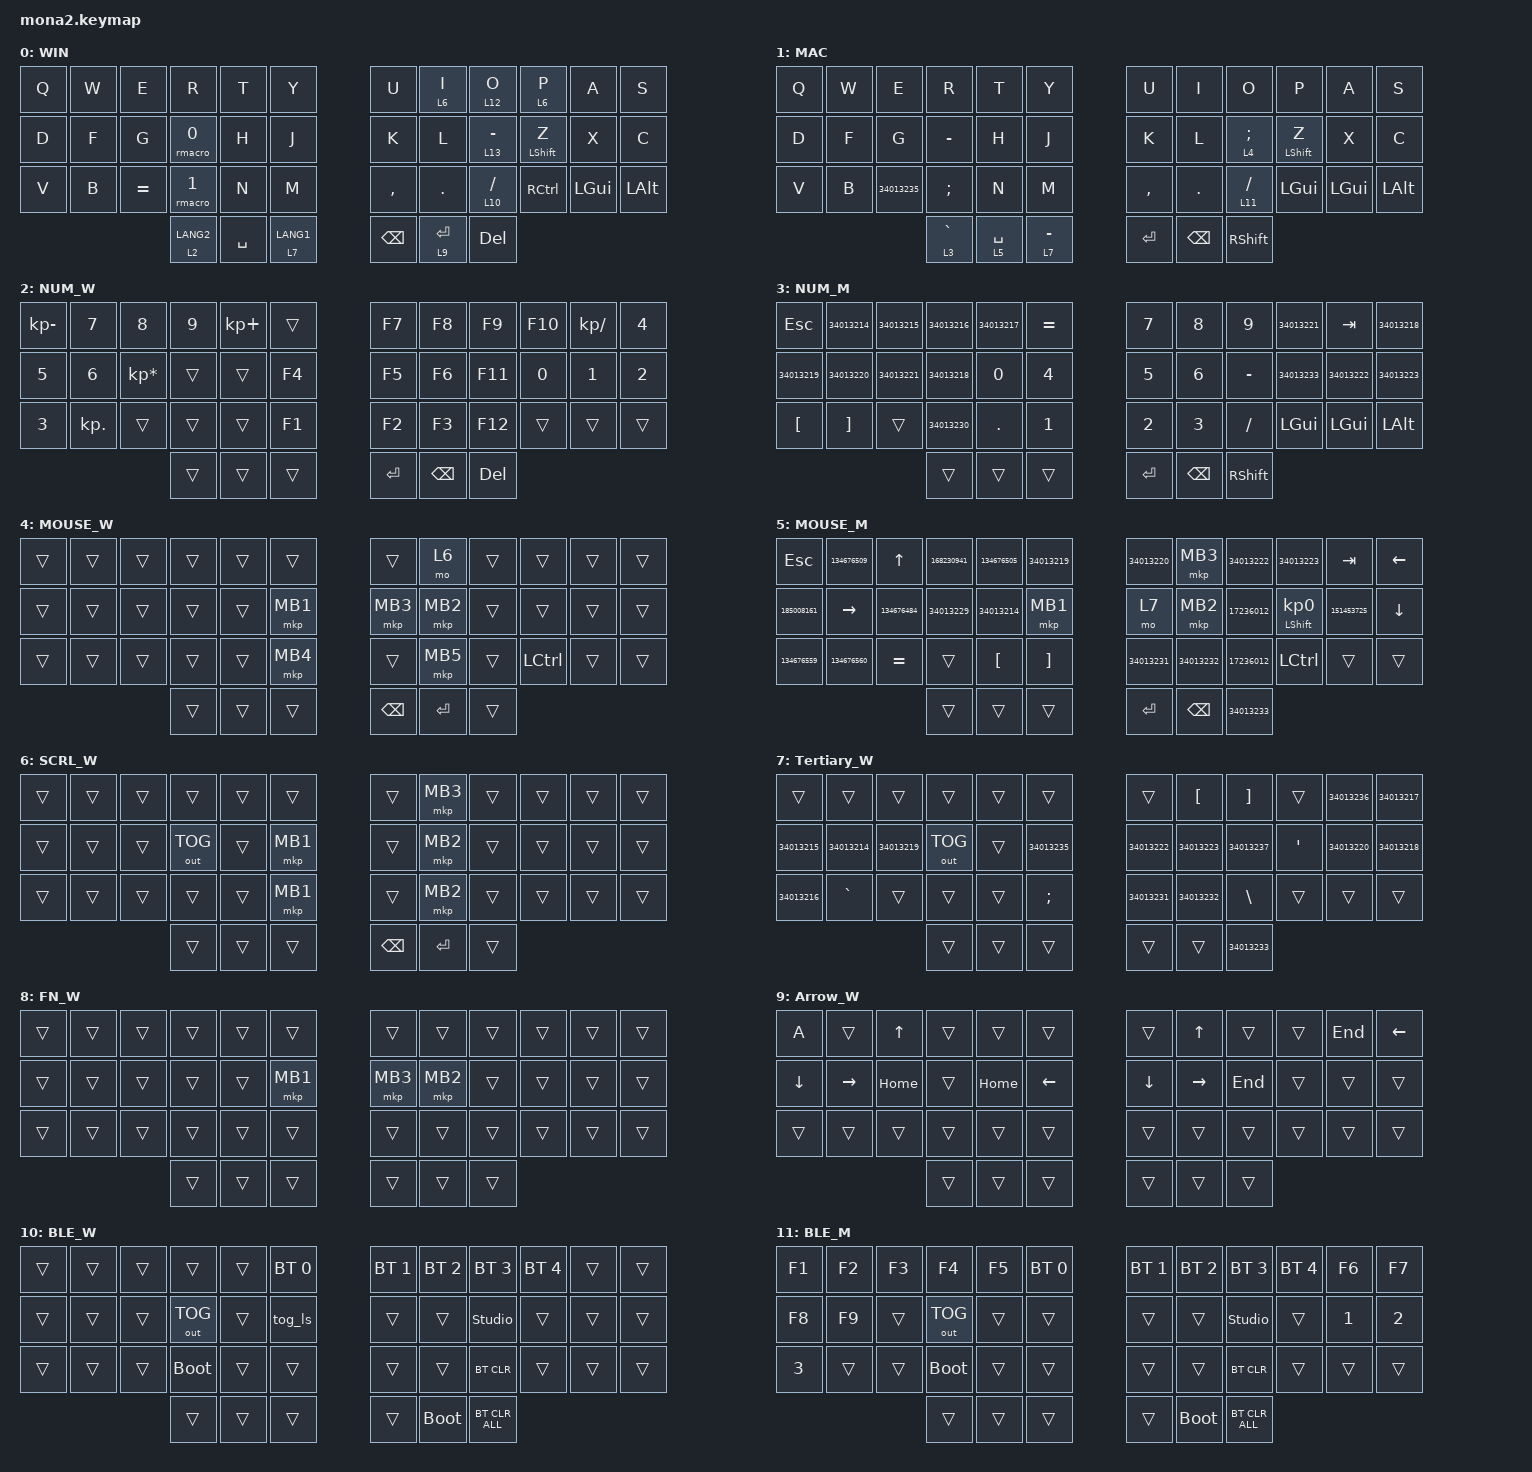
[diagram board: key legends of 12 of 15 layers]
#include <input/processors.dtsi>
#include <dt-bindings/zmk/input_transform.h>
#include <zephyr/dt-bindings/input/input-event-codes.h>
#include <behaviors/runtime-sensor-rotate.dtsi>
#include <behaviors.dtsi>
/* JIS配列のPCでもUS配列の刻印どおりに記号を入力するためのモジュール
   (modules/jis_layout_shift)。`&kp` を配列対応版に差し替え、`&tog_ls` で
   JIS変換の ON/OFF を切り替える。`&kp` のデバイス名 (key_press) と表示名は
   変えていないので、DYA Studio で保存済みのキーマップ / マクロ / コンボはそのまま使える。
   必ず behaviors.dtsi の後に include すること。 */
#include <jis_layout_shift.dtsi>
/* DYA Studio から作成したマクロを呼び出す `&rmacro <slot>` を定義する。
   slot は 0 〜 CONFIG_ZMK_RUNTIME_MACRO_COUNT-1 (現状 0〜7)。
   どのマクロがどのスロットに入っているかは DYA Studio のマクロ一覧で確認する。
   キーへの割り当ては DYA Studio のキーマップエディタからも行える。 */
#include <behaviors/runtime_macro.dtsi>
/* デフォルトレイヤー変更 behavior `&df`。
   DYA Studio の「OSごとのデフォルトレイヤー」から設定できるほか、
   キーマップエディタで `&df DF_SEL <layer>` / `&df DF_INC` を
   任意のキーに割り当てられる。 */
#include <behaviors/default_layer.dtsi>
#include <dt-bindings/zmk_behavior_default_layer/default_layer.h>
#include <dt-bindings/zmk/bt.h>
#include <dt-bindings/zmk/keys.h>
#include <dt-bindings/zmk/outputs.h>
#include <dt-bindings/zmk/pointing.h>

/* ZMK 側で 10 が定義済みなので警告回避のため一旦 undef */

#undef ZMK_POINTING_DEFAULT_SCRL_VAL

#define ZMK_POINTING_DEFAULT_SCRL_VAL 100


/ {
    behaviors {
        mg_set_0: behavior_mg_set_0 {
            compatible = "zmk,behavior-mg-set-fixed";
            #binding-cells = <0>;
            display-name = "Mouse Gesture Key 0";
        };

        mg_set_1: behavior_mg_set_1 {
            compatible = "zmk,behavior-mg-set-fixed";
            #binding-cells = <0>;
            display-name = "Mouse Gesture Key 1";
        };

        mg_set_2: behavior_mg_set_2 {
            compatible = "zmk,behavior-mg-set-fixed";
            #binding-cells = <0>;
            display-name = "Mouse Gesture Key 2";
        };
    };
};

&mt {
    flavor = "balanced";
    quick-tap-ms = <0>;
};

&lt {
    quick-tap-ms = <200>;
    flavor = "balanced";
};

&msc {
    delay-ms = <0>;
    time-to-max-speed-ms = <0>;
    acceleration-exponent = <0>;
};

/ {
    /* ─────────────────────────────────────────────────────────────
       コンボ (DYA Studio から編集可能)

       旧 `combos { compatible = "zmk,combos"; }` はコンパイル時固定で
       DYA Studio から編集できないため、zmk-feature-runtime-combo の
       「コンパイル時デフォルト」ノードへ移行した。
       ここに書いた内容はフラッシュ直後から有効で、設定を消しても復活する。
       DYA Studio 側で編集するとそのスロットだけ上書きされ、
       Web UI の "Reset to Default" でここの値へ戻せる。

       スロット総数は CONFIG_ZMK_RUNTIME_COMBO_MAX_COMBOS (現状 16)。
       未使用スロット (2〜15) は DYA Studio から自由に追加できる。
       ────────────────────────────────────────────────────────── */
    runtime_combo_defaults {
        compatible = "cormoran,runtime-combo-defaults";

        layer4_ESC {
            slot = <0>;
            display-name = "Layer4 ESC";
            key-positions = <38 39>;
            bindings = <&lt 4 ESC>;
        };

        tab {
            slot = <1>;
            display-name = "Tab";
            key-positions = <11 12>;
            bindings = <&kp TAB>;
        };

        /* I+O (位置7+8) → ボールジェスチャー ウィンドウ切替 */
        gesture_switch_combo {
            slot = <2>;
            display-name = "GestureSwitch";
            key-positions = <7 8>;
            bindings = <&gesture_switch>;
        };
    };

    /* 静的マクロ。キーマップ上で &BT0 / &screenshot などの名前で直接
       参照しているため、そのまま残している (DYA Studio 上では編集不可)。
       DYA Studio から編集したいマクロは Web UI で新規作成し、
       キーに `&rmacro <slot>` を割り当てて使う。 */
    macros {
        /* I+O コンボで発動: 押している間 gesture_switch 層(14)+抑制、
         * 離したら alt_tab_end で Alt+Tab 選択を確定する。 */
        gesture_switch: gesture_switch {
            compatible = "zmk,behavior-macro";
            #binding-cells = <0>;
            bindings = <&macro_press &mo 14>
                     , <&macro_pause_for_release>
                     , <&macro_release &mo 14>
                     , <&macro_tap &alt_tab_end>;
        };

        to_layer_0: to_layer_0 {
            compatible = "zmk,behavior-macro-one-param";
            #binding-cells = <1>;
            bindings = <&to 0 &macro_param_1to1 &kp MACRO_PLACEHOLDER>;
            label = "TO_LAYER_0";
        };

        BT0: BT0 {
            compatible = "zmk,behavior-macro";
            #binding-cells = <0>;
            bindings =
                <&tog_off 0 &tog_off 1>,
                <&macro_wait_time 200>,
                <&bt BT_SEL 0>,
                <&macro_wait_time 500>,
                <&tog_on 0>;

            label = "BT0";
        };

        BT1: BT1 {
            compatible = "zmk,behavior-macro";
            #binding-cells = <0>;
            bindings =
                <&tog_off 0 &tog_off 1>,
                <&macro_wait_time 200>,
                <&bt BT_SEL 1>,
                <&macro_wait_time 500>,
                <&tog_on 1>;

            label = "BT1";
        };

        screenshot: screenshot {
            compatible = "zmk,behavior-macro";
            #binding-cells = <0>;
            bindings =
                <&macro_press>,
                <&kp LEFT_GUI &kp RSHIFT>,
                <&macro_wait_time 20>,
                <&macro_tap>,
                <&kp S>,
                <&macro_release>,
                <&kp LEFT_GUI &kp RSHIFT>;

            label = "SCREENSHOT";
        };

        henkan: henkan {
            compatible = "zmk,behavior-macro";
            #binding-cells = <0>;
            bindings =
                <&macro_press>,
                <&kp LEFT_ALT>,
                <&macro_wait_time 20>,
                <&macro_tap>,
                /* IME 切替キーなので JIS 変換の対象外 (&kp_raw) にする */
                <&kp_raw GRAVE>,
                <&macro_release>,
                <&kp LEFT_ALT>;

            label = "HENKAN";
        };
    };

    behaviors {
        lt_to_layer_0: lt_to_layer_0 {
            compatible = "zmk,behavior-hold-tap";
            label = "LAYER_TAP_TO_0";
            bindings = <&mo>, <&to_layer_0>;

            #binding-cells = <2>;
            tapping-term-ms = <200>;
        };

        tp_repeat_mo1: tp_repeat_mo1 {
            compatible = "zmk,behavior-hold-tap";
            label = "TP_REPEAT_MO1";
            bindings = <&mo>, <&key_repeat>;

            #binding-cells = <2>;
            tapping-term-ms = <200>;
        };

        /* ── torabo-tsuki 流 ボールジェスチャー (Path B 移植) ──────────
         * O 長押し(&lt 12 O) → gesture_tab 層 / − 長押し(&lt 13 MINUS) → gesture_edit 層
         * I+O コンボ → gesture_switch 層(14)
         * ジェスチャー本体 (4方向→動作, always-active) と、その層にいる間の
         * カーソル抑制 (&xy_block) は boards/shields/mona2/mona2_r.overlay 側。
         * 発動キーは素の &lt / &mo なので抑制は listener override が担当する。 */

        /* Alt+Tab ウィンドウ切替 (modules/jis_layout_shift/src/behavior_alt_tab.c)。
         * 初回は LALT を押し続けて param1 をタップ、以降は param2 をタップ。
         * alt_tab_end で LALT を離して確定。central 限定ビルド。 */
        alt_tab: alt_tab {
            compatible = "zmk,behavior-alt-tab";
            #binding-cells = <2>;
        };
        alt_tab_end: alt_tab_end {
            compatible = "zmk,behavior-alt-tab-end";
            #binding-cells = <0>;
        };

        // エンコーダ用 runtime-configurable sensor rotate
        // デフォルトはスクロール (cw=SCRL_DOWN, ccw=SCRL_UP)
        // DYA Studio Web UI から レイヤーごとに cw/ccw の binding を
        // kp C_VOL_UP/DN や kp LEFT/RIGHT などへ動的変更可能

        rsr_default: rsr_default {
            compatible = "zmk,behavior-runtime-sensor-rotate";
            #sensor-binding-cells = <0>;
            tap-ms = <16>;
            cw-binding = <&msc SCRL_DOWN>;
            ccw-binding = <&msc SCRL_UP>;
        };

        tog_on: toggle_layer_on_only {
            compatible = "zmk,behavior-toggle-layer";
            #binding-cells = <1>;
            display-name = "Toggle Layer On";
            toggle-mode = "on";
        };

        tog_off: toggle_layer_off_only {
            compatible = "zmk,behavior-toggle-layer";
            #binding-cells = <1>;
            display-name = "Toggle Layer Off";
            toggle-mode = "off";
        };

        zfold: zfold {
            compatible = "zmk,behavior-hold-tap";
            label = "ZFOLD";
            bindings = <&kp>, <&kp>;

            #binding-cells = <2>;
            tapping-term-ms = <300>;
            flavor = "hold-preferred";
            quick-tap-ms = <150>;
            hold-while-undecided;
        };

        zfoldZ: zfoldZ {
            compatible = "zmk,behavior-tap-dance";
            label = "ZFOLDZ";
            #binding-cells = <0>;
            bindings = <&zfold LEFT_SHIFT Z>, <&kp LS(Z)>;
        };
    };

    keymap {
        compatible = "zmk,keymap";

        win_layer {
            display-name = "WIN";
            bindings = <
                &kp Q    &kp W    &kp E    &kp R    &kp T    &kp Y    &kp U    &lt 6 I    &lt 12 O    &lt 6 P    &kp A    &kp S
                &kp D    &kp F    &kp G    &rmacro 0    &kp H    &kp J    &kp K    &kp L    &lt 13 MINUS    &mt LEFT_SHIFT Z    &kp X    &kp C
                &kp V    &kp B    &kp EQUAL    &rmacro 1    &kp N    &kp M    &kp COMMA    &kp PERIOD    &lt 10 SLASH    &kp RIGHT_CONTROL    &kp LEFT_GUI    &kp LEFT_ALT
                &lt 2 LANG2    &kp SPACE    &lt 7 LANG1    &kp BACKSPACE    &lt 9 RETURN    &kp DELETE
            >;
            sensor-bindings = <&rsr_default>, <&inc_dec_kp C_VOL_DN C_VOL_UP>;
        };

        mac_layer {
            display-name = "MAC";
            bindings = <
                &kp Q    &kp W    &kp E    &kp R    &kp T    &kp Y    &kp U    &kp I    &kp O    &kp P    &kp A    &kp S
                &kp D    &kp F    &kp G    &kp MINUS    &kp H    &kp J    &kp K    &kp L    &lt 4 SEMICOLON    &mt LEFT_SHIFT Z    &kp X    &kp C
                &kp V    &kp B    &kp 34013235    &kp SEMICOLON    &kp N    &kp M    &kp COMMA    &kp PERIOD    &lt 11 SLASH    &kp LEFT_GUI    &kp LEFT_GUI    &kp LEFT_ALT
                &lt 3 GRAVE    &lt 5 SPACE    &lt 7 MINUS    &kp RETURN    &kp BACKSPACE    &kp RIGHT_SHIFT
            >;
            sensor-bindings = <&rsr_default>, <&inc_dec_kp C_VOL_DN C_VOL_UP>;
        };

        num_w_layer {
            display-name = "NUM_W";
            bindings = <
                &kp KP_MINUS    &kp N7    &kp N8    &kp N9    &kp KP_PLUS    &trans    &kp F7    &kp F8    &kp F9    &kp F10    &kp KP_SLASH    &kp N4
                &kp N5    &kp N6    &kp KP_ASTERISK    &trans    &trans    &kp F4    &kp F5    &kp F6    &kp F11    &kp N0    &kp N1    &kp N2
                &kp N3    &kp KP_DOT    &trans    &trans    &trans    &kp F1    &kp F2    &kp F3    &kp F12    &trans    &trans    &trans
                &trans    &trans    &trans    &kp RETURN    &kp BACKSPACE    &kp DELETE
            >;
            sensor-bindings = <&rsr_default>;
        };

        num_m_layer {
            display-name = "NUM_M";
            bindings = <
                &kp ESCAPE    &kp 34013214    &kp 34013215    &kp 34013216    &kp 34013217    &kp EQUAL    &kp N7    &kp N8    &kp N9    &kp 34013221    &kp TAB    &kp 34013218
                &kp 34013219    &kp 34013220    &kp 34013221    &kp 34013218    &kp N0    &kp N4    &kp N5    &kp N6    &kp MINUS    &kp 34013233    &kp 34013222    &kp 34013223
                &kp LEFT_BRACKET    &kp RIGHT_BRACKET    &trans    &kp 34013230    &kp PERIOD    &kp N1    &kp N2    &kp N3    &kp SLASH    &kp LEFT_GUI    &kp LEFT_GUI    &kp LEFT_ALT
                &trans    &trans    &trans    &kp RETURN    &kp BACKSPACE    &kp RIGHT_SHIFT
            >;
            sensor-bindings = <&rsr_default>;
        };

        mouse_w_layer {
            display-name = "MOUSE_W";
            bindings = <
                &trans    &trans    &trans    &trans    &trans    &trans    &trans    &mo 6    &trans    &trans    &trans    &trans
                &trans    &trans    &trans    &trans    &trans    &mkp MB1    &mkp MB3    &mkp MB2    &trans    &trans    &trans    &trans
                &trans    &trans    &trans    &trans    &trans    &mkp MB4    &trans    &mkp MB5    &trans    &kp LEFT_CONTROL    &trans    &trans
                &trans    &trans    &trans    &kp BACKSPACE    &kp RETURN    &trans
            >;
            sensor-bindings = <&rsr_default>;
        };

        mouse_m_layer {
            display-name = "MOUSE_M";
            bindings = <
                &kp ESCAPE    &kp 134676509    &kp UP    &kp 168230941    &kp 134676505    &kp 34013219    &kp 34013220    &mkp MB3    &kp 34013222    &kp 34013223    &kp TAB    &kp LEFT
                &kp 185008161    &kp RIGHT    &kp 134676484    &kp 34013229    &kp 34013214    &mkp MB1    &mo 7    &mkp MB2    &kp 17236012    &mt LEFT_SHIFT KP_N0    &kp 151453725    &kp DOWN
                &kp 134676559    &kp 134676560    &kp EQUAL    &trans    &kp LEFT_BRACKET    &kp RIGHT_BRACKET    &kp 34013231    &kp 34013232    &kp 17236012    &kp LEFT_CONTROL    &trans    &trans
                &trans    &trans    &trans    &kp RETURN    &kp BACKSPACE    &kp 34013233
            >;
            sensor-bindings = <&rsr_default>;
        };

        scrl_w_layer {
            display-name = "SCRL_W";
            bindings = <
                &trans    &trans    &trans    &trans    &trans    &trans    &trans    &mkp MB3    &trans    &trans    &trans    &trans
                &trans    &trans    &trans    &out OUT_TOG    &trans    &mkp MB1    &trans    &mkp MB2    &trans    &trans    &trans    &trans
                &trans    &trans    &trans    &trans    &trans    &mkp MB1    &trans    &mkp MB2    &trans    &trans    &trans    &trans
                &trans    &trans    &trans    &kp BACKSPACE    &kp RETURN    &trans
            >;
            sensor-bindings = <&rsr_default>;
        };

        tertiary_w_layer {
            display-name = "Tertiary_W";
            bindings = <
                &trans    &trans    &trans    &trans    &trans    &trans    &trans    &kp LEFT_BRACKET    &kp RIGHT_BRACKET    &trans    &kp 34013236    &kp 34013217
                &kp 34013215    &kp 34013214    &kp 34013219    &out OUT_TOG    &trans    &kp 34013235    &kp 34013222    &kp 34013223    &kp 34013237    &kp SQT    &kp 34013220    &kp 34013218
                &kp 34013216    &kp GRAVE    &trans    &trans    &trans    &kp SEMICOLON    &kp 34013231    &kp 34013232    &kp BACKSLASH    &trans    &trans    &trans
                &trans    &trans    &trans    &trans    &trans    &kp 34013233
            >;
            sensor-bindings = <&rsr_default>;
        };

        fn_w_layer {
            display-name = "FN_W";
            bindings = <
                &trans    &trans    &trans    &trans    &trans    &trans    &trans    &trans    &trans    &trans    &trans    &trans
                &trans    &trans    &trans    &trans    &trans    &mkp MB1    &mkp MB3    &mkp MB2    &trans    &trans    &trans    &trans
                &trans    &trans    &trans    &trans    &trans    &trans    &trans    &trans    &trans    &trans    &trans    &trans
                &trans    &trans    &trans    &trans    &trans    &trans
            >;
            sensor-bindings = <&rsr_default>;
        };

        arrow_w_layer {
            display-name = "Arrow_W";
            bindings = <
                &kp A    &trans    &kp UP    &trans    &trans    &trans    &trans    &kp UP    &trans    &trans    &kp END    &kp LEFT
                &kp DOWN    &kp RIGHT    &kp HOME    &trans    &kp HOME    &kp LEFT    &kp DOWN    &kp RIGHT    &kp END    &trans    &trans    &trans
                &trans    &trans    &trans    &trans    &trans    &trans    &trans    &trans    &trans    &trans    &trans    &trans
                &trans    &trans    &trans    &trans    &trans    &trans
            >;
            sensor-bindings = <&rsr_default>;
        };

        ble_w_layer {
            display-name = "BLE_W";
            bindings = <
                &trans    &trans    &trans    &trans    &trans    &bt BT_SEL 0    &bt BT_SEL 1    &bt BT_SEL 2    &bt BT_SEL 3    &bt BT_SEL 4    &trans    &trans
                &trans    &trans    &trans    &out OUT_TOG    &trans    &tog_ls    &trans    &trans    &studio_unlock    &trans    &trans    &trans
                &trans    &trans    &trans    &bootloader    &trans    &trans    &trans    &trans    &bt BT_CLR    &trans    &trans    &trans
                &trans    &trans    &trans    &trans    &bootloader    &bt BT_CLR_ALL
            >;
            sensor-bindings = <&rsr_default>;
        };

        ble_m_layer {
            display-name = "BLE_M";
            bindings = <
                &kp F1    &kp F2    &kp F3    &kp F4    &kp F5    &bt BT_SEL 0    &bt BT_SEL 1    &bt BT_SEL 2    &bt BT_SEL 3    &bt BT_SEL 4    &kp F6    &kp F7
                &kp F8    &kp F9    &trans    &out OUT_TOG    &trans    &trans    &trans    &trans    &studio_unlock    &trans    &kp N1    &kp N2
                &kp N3    &trans    &trans    &bootloader    &trans    &trans    &trans    &trans    &bt BT_CLR    &trans    &trans    &trans
                &trans    &trans    &trans    &trans    &bootloader    &bt BT_CLR_ALL
            >;
            sensor-bindings = <&rsr_default>;
        };

        /* ── ボールジェスチャー層 (torabo 移植, index 12/13/14) ──────
         * すべて &trans: このキーの長押し/コンボで入り、ボールを転がして
         * ジェスチャーを出すだけの層。実際の 4方向→動作は overlay 側の
         * mg_tab/mg_edit/mg_switch と listener override が担う。 */
        gesture_tab_layer {
            display-name = "G_TAB";
            bindings = <
                &trans    &trans    &trans    &trans    &trans    &trans    &trans    &trans    &trans    &trans    &trans    &trans
                &trans    &trans    &trans    &trans    &trans    &trans    &trans    &trans    &trans    &trans    &trans    &trans
                &trans    &trans    &trans    &trans    &trans    &trans    &trans    &trans    &trans    &trans    &trans    &trans
                &trans    &trans    &trans    &trans    &trans    &trans
            >;
            sensor-bindings = <&rsr_default>;
        };

        gesture_edit_layer {
            display-name = "G_EDIT";
            bindings = <
                &trans    &trans    &trans    &trans    &trans    &trans    &trans    &trans    &trans    &trans    &trans    &trans
                &trans    &trans    &trans    &trans    &trans    &trans    &trans    &trans    &trans    &trans    &trans    &trans
                &trans    &trans    &trans    &trans    &trans    &trans    &trans    &trans    &trans    &trans    &trans    &trans
                &trans    &trans    &trans    &trans    &trans    &trans
            >;
            sensor-bindings = <&rsr_default>;
        };

        gesture_switch_layer {
            display-name = "G_SWITCH";
            bindings = <
                &trans    &trans    &trans    &trans    &trans    &trans    &trans    &trans    &trans    &trans    &trans    &trans
                &trans    &trans    &trans    &trans    &trans    &trans    &trans    &trans    &trans    &trans    &trans    &trans
                &trans    &trans    &trans    &trans    &trans    &trans    &trans    &trans    &trans    &trans    &trans    &trans
                &trans    &trans    &trans    &trans    &trans    &trans
            >;
            sensor-bindings = <&rsr_default>;
        };
    };
};
